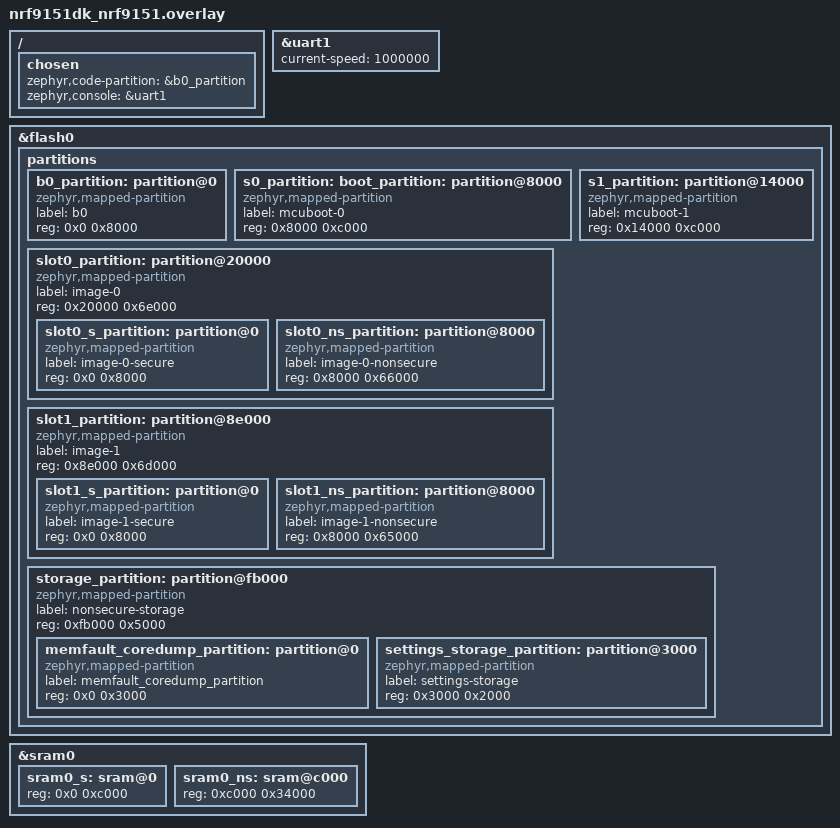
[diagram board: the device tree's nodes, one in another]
/*
 * Copyright (c) 2026 Nordic Semiconductor ASA
 *
 * SPDX-License-Identifier: LicenseRef-Nordic-5-Clause
 */

/ {
	chosen {
		zephyr,code-partition = &b0_partition;
		zephyr,console = &uart1;
	};
};

&uart1 {
	current-speed = <1000000>;
	status = "okay";
};

/*
 * Flash partition layout for nRF9151 DK (same with B0, MCUboot and application):
 *
 * 0x0000_0000  b0 (NSIB)                    ( 32 kB)
 * 0x0000_8000  s0 (MCUBoot image, slot 0)   ( 48 kB)
 * 0x0001_4000  s1 (MCUBoot image, slot 1)   ( 48 kB)
 * 0x0002_0000  slot0 (primary app)          (440 kB)
 *   0x0002_0000  TF-M secure                ( 32 kB)
 *   0x0002_8000  Application (non-secure)   (408 kB - (MCUBoot swap sector + MCUboot trailer))
 * 0x0008_e000  slot1 (secondary app)        (436 kB)
 * 0x000f_b000  storage (container)          ( 20 kB)
 *   0x000f_b000  Memfault core dump         ( 12 kB)
 *   0x000f_e000  Non-secure storage         (  8 kB)
 */

/delete-node/ &boot_partition;
/delete-node/ &slot0_partition;
/delete-node/ &slot1_partition;
/delete-node/ &tfm_ps_partition;
/delete-node/ &tfm_its_partition;
/delete-node/ &tfm_otp_partition;
/delete-node/ &storage_partition;

&flash0 {
	partitions {
		b0_partition: partition@0 {
			compatible = "zephyr,mapped-partition";
			label = "b0";
			reg = <0x0 0x8000>;
		};

		s0_partition: boot_partition: partition@8000 {
			compatible = "zephyr,mapped-partition";
			label = "mcuboot-0";
			reg = <0x8000 0xc000>;
		};

		s1_partition: partition@14000 {
			compatible = "zephyr,mapped-partition";
			label = "mcuboot-1";
			reg = <0x14000 0xc000>;
		};

		slot0_partition: partition@20000 {
			compatible = "zephyr,mapped-partition";
			label = "image-0";
			reg = <0x20000 0x6e000>;
			ranges = <0x0 0x20000 0x6e000>;
			#address-cells = <1>;
			#size-cells = <1>;

			slot0_s_partition: partition@0 {
				compatible = "zephyr,mapped-partition";
				label = "image-0-secure";
				reg = <0x0 0x8000>;
			};

			slot0_ns_partition: partition@8000 {
				compatible = "zephyr,mapped-partition";
				label = "image-0-nonsecure";
				reg = <0x8000 0x66000>;
			};
		};

		slot1_partition: partition@8e000 {
			compatible = "zephyr,mapped-partition";
			label = "image-1";
			reg = <0x8e000 0x6d000>;
			ranges = <0x0 0x8e000 0x6d000>;
			#address-cells = <1>;
			#size-cells = <1>;

			slot1_s_partition: partition@0 {
				compatible = "zephyr,mapped-partition";
				label = "image-1-secure";
				reg = <0x0 0x8000>;
			};

			slot1_ns_partition: partition@8000 {
				compatible = "zephyr,mapped-partition";
				label = "image-1-nonsecure";
				reg = <0x8000 0x65000>;
			};
		};

		storage_partition: partition@fb000 {
			compatible = "zephyr,mapped-partition";
			label = "nonsecure-storage";
			reg = <0xfb000 0x5000>;
			ranges = <0x0 0xfb000 0x5000>;
			#address-cells = <1>;
			#size-cells = <1>;

			memfault_coredump_partition: partition@0 {
				compatible = "zephyr,mapped-partition";
				label = "memfault_coredump_partition";
				reg = <0x0 0x3000>;
			};

			settings_storage_partition: partition@3000 {
				compatible = "zephyr,mapped-partition";
				label = "settings-storage";
				reg = <0x3000 0x2000>;
			};
		};
	};
};

/* B0 SRAM layout for nRF9151 DK (same with B0 and MCUboot):
 *
 * Important: Use the same SRAM layout in B0 and MCUboot.
 *
 * Ensures that zeroing the secure RAM in MCUboot also clears the secure RAM used by B0.
 *
 * 0x2000_0000  Secure RAM                   (  48 kB)
 * 0x2000_c000  Non-secure RAM area          ( 208 kB)
 */

/delete-node/ &sram0_s;
/delete-node/ &sram0_ns;

&sram0 {

	sram0_s: sram@0 {
		reg = <0x0 0xc000>;
	};

	sram0_ns: sram@c000 {
		reg = <0xc000 0x34000>;
	};
};
